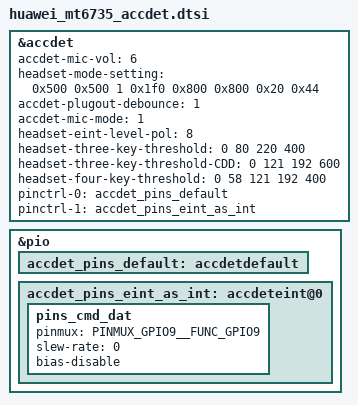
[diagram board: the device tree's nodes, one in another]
/* accdet start */
&accdet {
    accdet-mic-vol = <6>;
    headset-mode-setting = <0x500 0x500 1 0x1f0 0x800 0x800 0x20 0x44>;
    accdet-plugout-debounce = <1>;
    accdet-mic-mode = <1>;
    headset-eint-level-pol = <8>;
    headset-three-key-threshold = <0 80 220 400>;
    headset-three-key-threshold-CDD = <0 121 192 600>;
    headset-four-key-threshold = <0 58 121 192 400>;
    pinctrl-names = "default", "state_eint_as_int";
    pinctrl-0 = <&accdet_pins_default>;
    pinctrl-1 = <&accdet_pins_eint_as_int>;
    status = "okay";
};
&pio {
    accdet_pins_default: accdetdefault {
    };
    accdet_pins_eint_as_int: accdeteint@0 {
        pins_cmd_dat {
            pinmux = <PINMUX_GPIO9__FUNC_GPIO9>;
            slew-rate = <0>;
            bias-disable;
        };
    };
};
/* accdet end */

